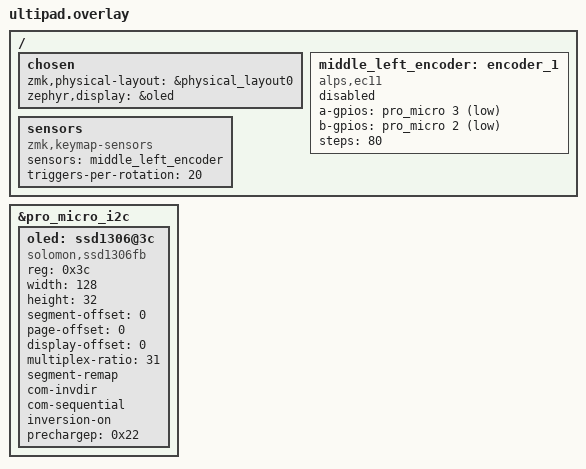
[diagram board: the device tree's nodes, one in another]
#include <dt-bindings/zmk/matrix_transform.h> // Put this with the other includes at the top of your overlay
#include <physical_layouts.dtsi>
#include "ultipad-layouts.dtsi"

/{

    chosen {
        zmk,physical-layout = &physical_layout0;
        zephyr,display = &oled;
    };

    middle_left_encoder: encoder_1: encoder_1 {
        compatible = "alps,ec11";
        a-gpios = <&pro_micro 3 (GPIO_ACTIVE_LOW | GPIO_PULL_UP)>;
        b-gpios = <&pro_micro 2 (GPIO_ACTIVE_LOW | GPIO_PULL_UP)>;
        steps = <80>;
        status = "disabled";
    };

    sensors: sensors {
        compatible = "zmk,keymap-sensors";
        sensors = <&middle_left_encoder>;
        triggers-per-rotation = <20>;
    };
};

&pro_micro_i2c {
    status = "okay";

    oled: ssd1306@3c {
        compatible = "solomon,ssd1306fb";
        reg = <0x3c>;
        width = <128>;
        height = <32>;
        segment-offset = <0>;
        page-offset = <0>;
        display-offset = <0>;
        multiplex-ratio = <31>;
        segment-remap;
        com-invdir;
        com-sequential;
        inversion-on;
        prechargep = <0x22>;
    };
};
